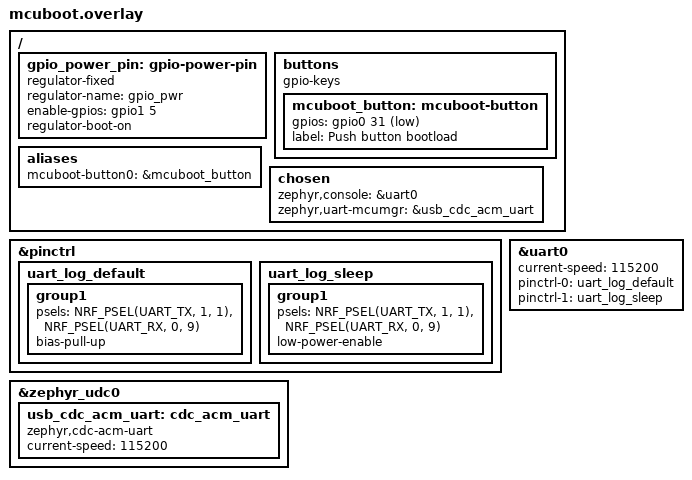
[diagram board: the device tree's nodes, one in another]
/*
 * SPDX-License-Identifier: Apache-2.0
 */

&pinctrl {
	uart_log_default: uart_log_default {
		group1 {
			psels = <NRF_PSEL(UART_TX, 1, 1)>,	// P1.01 - B2 - logger - uart tx
			        <NRF_PSEL(UART_RX, 0, 9)>;	// P0.09 - B1 - dummy - uart rx
		bias-pull-up;
	  };
	};
	uart_log_sleep: uart_log_sleep {
	  	group1 {
			psels = <NRF_PSEL(UART_TX, 1, 1)>,	// P1.01 - B2 - logger
					<NRF_PSEL(UART_RX, 0, 9)>;	// P0.09 - B1 - dummy - uart rx
		low-power-enable;
	  	};
	};
};

&uart0 {
	status = "okay";
	current-speed = <115200>;
	pinctrl-0 = <&uart_log_default>;
	pinctrl-1 = <&uart_log_sleep>;
	pinctrl-names = "default", "sleep";
};

/ {
    gpio_power_pin: gpio-power-pin { // turn on 1v8 power for U5 in case we have UART logger
        compatible = "regulator-fixed";
        regulator-name = "gpio_pwr";
        enable-gpios = <&gpio1 5 GPIO_ACTIVE_HIGH>;
        regulator-boot-on;
    };

	buttons { // bootloder mode turned on by SW2 press
		compatible = "gpio-keys";
		mcuboot_button: mcuboot-button {
			gpios = <&gpio0 31 (GPIO_PULL_UP | GPIO_ACTIVE_LOW)>;
			label = "Push button bootload";
		};
	};

	aliases {
		mcuboot-button0 = &mcuboot_button;
	};
	
	chosen { // uart 0 used for logger,usb-uart for mcuboot
		zephyr,console = &uart0;
		zephyr,uart-mcumgr=&usb_cdc_acm_uart;
	};
};

&zephyr_udc0 {
	usb_cdc_acm_uart: cdc_acm_uart {
		compatible = "zephyr,cdc-acm-uart";
		current-speed = <115200>;
		status = "okay";
	};
};

